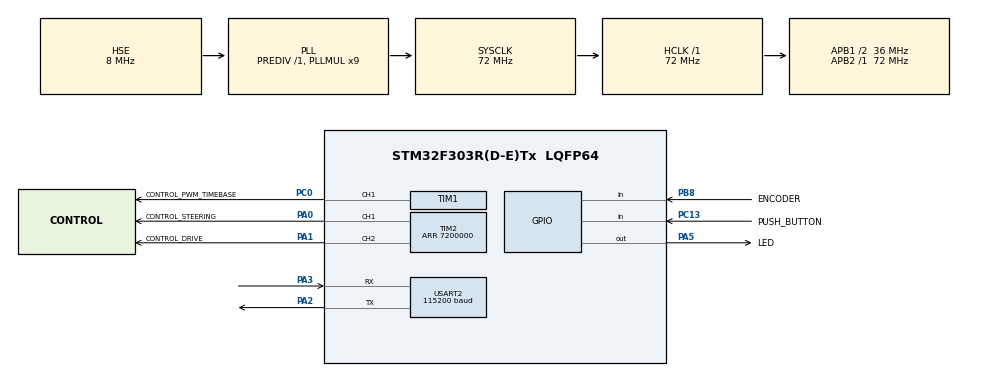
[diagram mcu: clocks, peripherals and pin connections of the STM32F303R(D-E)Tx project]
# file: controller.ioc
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FREERTOS.Tasks01=defaultTask,24,128,StartDefaultTask,Default,NULL,Dynamic,NULL,NULL
Mcu.Family=STM32F3
Mcu.Name=STM32F303R(D-E)Tx
Mcu.Package=LQFP64
NVIC.PriorityGroup=NVIC_PRIORITYGROUP_4
NVIC.USART2_IRQn=true\:5\:0\:false\:false\:true\:true\:true\:true
PA0.GPIO_Label=CONTROL_STEERING
PA0.Signal=S_TIM2_CH1_ETR
PA1.GPIO_Label=CONTROL_DRIVE
PA1.Signal=S_TIM2_CH2
PA2.Mode=Asynchronous
PA2.Signal=USART2_TX
PA3.Mode=Asynchronous
PA3.Signal=USART2_RX
PA5.GPIO_Label=LED
PA5.Signal=GPIO_Output
PB8.GPIO_Label=ENCODER
PB8.GPIO_PuPd=GPIO_PULLUP
PB8.Signal=GPIO_Input
PC0.GPIO_Label=CONTROL_PWM_TIMEBASE
PC0.Signal=S_TIM1_CH1
PC13.GPIO_Label=PUSH_BUTTON
PC13.Signal=GPIO_Input
PF0-OSC_IN.Mode=HSE-External-Oscillator
PF0-OSC_IN.Signal=RCC_OSC_IN
PF1-OSC_OUT.Mode=HSE-External-Oscillator
PF1-OSC_OUT.Signal=RCC_OSC_OUT
ProjectManager.HeapSize=0x200
ProjectManager.StackSize=0x400
ProjectManager.TargetToolchain=STM32CubeIDE
RCC.AHBFreq_Value=72000000
RCC.APB1CLKDivider=RCC_HCLK_DIV2
RCC.APB1Freq_Value=36000000
RCC.APB1TimFreq_Value=72000000
RCC.APB2Freq_Value=72000000
RCC.APB2TimFreq_Value=72000000
RCC.CortexFreq_Value=72000000
RCC.HCLKFreq_Value=72000000
RCC.HSE_VALUE=8000000
RCC.HSI_VALUE=8000000
RCC.LSE_VALUE=32768
RCC.PLLMUL=RCC_PLL_MUL9
RCC.PLLSourceVirtual=RCC_PLLSOURCE_HSE
RCC.RCC_MCODiv=RCC_MCODIV_128
RCC.SYSCLKFreq_VALUE=72000000
RCC.SYSCLKSourceVirtual=RCC_SYSCLKSOURCE_PLLCLK
RCC.USBFreq_Value=72000000
SH.S_TIM1_CH1.0=TIM1_CH1,PWM Generation1 CH1
SH.S_TIM2_CH1_ETR.0=TIM2_CH1,PWM Generation1 CH1
SH.S_TIM2_CH2.0=TIM2_CH2,PWM Generation2 CH2
TIM1.AutoReloadPreload=TIM_AUTORELOAD_PRELOAD_ENABLE
TIM1.Channel-PWM\ Generation1\ CH1=TIM_CHANNEL_1
TIM1.Period=9999
TIM1.Prescaler=71
TIM1.Pulse-PWM\ Generation1\ CH1=5000
TIM1.TIM_MasterOutputTrigger=TIM_TRGO_UPDATE
TIM2.Channel-PWM\ Generation1\ CH1=TIM_CHANNEL_1
TIM2.Channel-PWM\ Generation2\ CH2=TIM_CHANNEL_2
TIM2.Period=7200000
TIM2.Pulse-PWM\ Generation1\ CH1=108000
TIM2.Pulse-PWM\ Generation2\ CH2=108000
USART2.BaudRate=115200
USART2.VirtualMode-Asynchronous=VM_ASYNC
VP_FREERTOS_VS_CMSIS_V2.Mode=CMSIS_V2
VP_TIM1_VS_ClockSourceINT.Mode=Internal
VP_TIM2_VS_ClockSourceINT.Mode=Internal
VP_TIM2_VS_ClockSourceITR.Mode=TriggerSource_ITR0
VP_TIM2_VS_ControllerModeCombinedResetTrigger.Mode=Combined_Reset_Trigger_Mode
board=custom

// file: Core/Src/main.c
/* USER CODE BEGIN Header */
/**
  ******************************************************************************
  * @file           : main.c
  * @brief          : Main program body
  ******************************************************************************
  * @attention
  *
  * <h2><center>&copy; Copyright (c) 2020 STMicroelectronics.
  * All rights reserved.</center></h2>
  *
  * This software component is licensed by ST under BSD 3-Clause license,
  * the "License"; You may not use this file except in compliance with the
  * License. You may obtain a copy of the License at:
  *                        opensource.org/licenses/BSD-3-Clause
  *
  ******************************************************************************
  */
/* USER CODE END Header */

#include "main.h"
#include "cmsis_os.h"

TIM_HandleTypeDef htim1;
TIM_HandleTypeDef htim2;

UART_HandleTypeDef huart2;

/* Definitions for defaultTask */
osThreadId_t defaultTaskHandle;
const osThreadAttr_t defaultTask_attributes = {
  .name = "defaultTask",
  .priority = (osPriority_t) osPriorityNormal,
  .stack_size = 128 * 4
};

void SystemClock_Config(void);
static void MX_GPIO_Init(void);
static void MX_TIM1_Init(void);
static void MX_TIM2_Init(void);
static void MX_USART2_UART_Init(void);
void StartDefaultTask(void *argument);

int main(void)
{

  /* MCU Configuration--------------------------------------------------------*/

  /* Reset of all peripherals, Initializes the Flash interface and the Systick. */
  HAL_Init();

  /* Configure the system clock */
  SystemClock_Config();

  /* Initialize all configured peripherals */
  MX_GPIO_Init();
  MX_TIM1_Init();
  MX_TIM2_Init();
  MX_USART2_UART_Init();

  /* Init scheduler */
  osKernelInitialize();

  /* Create the thread(s) */
  /* creation of defaultTask */
  defaultTaskHandle = osThreadNew(StartDefaultTask, NULL, &defaultTask_attributes);

  /* Start scheduler */
  osKernelStart();

  /* We should never get here as control is now taken by the scheduler */
  /* Infinite loop */
  while (1)
  {

  }
}

void SystemClock_Config(void)
{
  RCC_OscInitTypeDef RCC_OscInitStruct = {0};
  RCC_ClkInitTypeDef RCC_ClkInitStruct = {0};
  RCC_PeriphCLKInitTypeDef PeriphClkInit = {0};

  /** Initializes the CPU, AHB and APB busses clocks
  */
  RCC_OscInitStruct.OscillatorType = RCC_OSCILLATORTYPE_HSE;
  RCC_OscInitStruct.HSEState = RCC_HSE_ON;
  RCC_OscInitStruct.HSIState = RCC_HSI_ON;
  RCC_OscInitStruct.PLL.PLLState = RCC_PLL_ON;
  RCC_OscInitStruct.PLL.PLLSource = RCC_PLLSOURCE_HSE;
  RCC_OscInitStruct.PLL.PLLMUL = RCC_PLL_MUL9;
  RCC_OscInitStruct.PLL.PREDIV = RCC_PREDIV_DIV1;
  if (HAL_RCC_OscConfig(&RCC_OscInitStruct) != HAL_OK)
  {
    Error_Handler();
  }
  /** Initializes the CPU, AHB and APB busses clocks
  */
  RCC_ClkInitStruct.ClockType = RCC_CLOCKTYPE_HCLK|RCC_CLOCKTYPE_SYSCLK
                              |RCC_CLOCKTYPE_PCLK1|RCC_CLOCKTYPE_PCLK2;
  RCC_ClkInitStruct.SYSCLKSource = RCC_SYSCLKSOURCE_PLLCLK;
  RCC_ClkInitStruct.AHBCLKDivider = RCC_SYSCLK_DIV1;
  RCC_ClkInitStruct.APB1CLKDivider = RCC_HCLK_DIV2;
  RCC_ClkInitStruct.APB2CLKDivider = RCC_HCLK_DIV1;

  if (HAL_RCC_ClockConfig(&RCC_ClkInitStruct, FLASH_LATENCY_2) != HAL_OK)
  {
    Error_Handler();
  }
  PeriphClkInit.PeriphClockSelection = RCC_PERIPHCLK_USART2|RCC_PERIPHCLK_TIM1
                              |RCC_PERIPHCLK_TIM2;
  PeriphClkInit.Usart2ClockSelection = RCC_USART2CLKSOURCE_PCLK1;
  PeriphClkInit.Tim1ClockSelection = RCC_TIM1CLK_HCLK;
  PeriphClkInit.Tim2ClockSelection = RCC_TIM2CLK_HCLK;
  if (HAL_RCCEx_PeriphCLKConfig(&PeriphClkInit) != HAL_OK)
  {
    Error_Handler();
  }
}

static void MX_TIM1_Init(void)
{

  TIM_ClockConfigTypeDef sClockSourceConfig = {0};
  TIM_MasterConfigTypeDef sMasterConfig = {0};
  TIM_OC_InitTypeDef sConfigOC = {0};
  TIM_BreakDeadTimeConfigTypeDef sBreakDeadTimeConfig = {0};

  htim1.Instance = TIM1;
  htim1.Init.Prescaler = 71;
  htim1.Init.CounterMode = TIM_COUNTERMODE_UP;
  htim1.Init.Period = 9999;
  htim1.Init.ClockDivision = TIM_CLOCKDIVISION_DIV1;
  htim1.Init.RepetitionCounter = 0;
  htim1.Init.AutoReloadPreload = TIM_AUTORELOAD_PRELOAD_ENABLE;
  if (HAL_TIM_Base_Init(&htim1) != HAL_OK)
  {
    Error_Handler();
  }
  sClockSourceConfig.ClockSource = TIM_CLOCKSOURCE_INTERNAL;
  if (HAL_TIM_ConfigClockSource(&htim1, &sClockSourceConfig) != HAL_OK)
  {
    Error_Handler();
  }
  if (HAL_TIM_PWM_Init(&htim1) != HAL_OK)
  {
    Error_Handler();
  }
  sMasterConfig.MasterOutputTrigger = TIM_TRGO_UPDATE;
  sMasterConfig.MasterOutputTrigger2 = TIM_TRGO2_RESET;
  sMasterConfig.MasterSlaveMode = TIM_MASTERSLAVEMODE_DISABLE;
  if (HAL_TIMEx_MasterConfigSynchronization(&htim1, &sMasterConfig) != HAL_OK)
  {
    Error_Handler();
  }
  sConfigOC.OCMode = TIM_OCMODE_PWM1;
  sConfigOC.Pulse = 5000;
  sConfigOC.OCPolarity = TIM_OCPOLARITY_HIGH;
  sConfigOC.OCNPolarity = TIM_OCNPOLARITY_HIGH;
  sConfigOC.OCFastMode = TIM_OCFAST_DISABLE;
  sConfigOC.OCIdleState = TIM_OCIDLESTATE_RESET;
  sConfigOC.OCNIdleState = TIM_OCNIDLESTATE_RESET;
  if (HAL_TIM_PWM_ConfigChannel(&htim1, &sConfigOC, TIM_CHANNEL_1) != HAL_OK)
  {
    Error_Handler();
  }
  sBreakDeadTimeConfig.OffStateRunMode = TIM_OSSR_DISABLE;
  sBreakDeadTimeConfig.OffStateIDLEMode = TIM_OSSI_DISABLE;
  sBreakDeadTimeConfig.LockLevel = TIM_LOCKLEVEL_OFF;
  sBreakDeadTimeConfig.DeadTime = 0;
  sBreakDeadTimeConfig.BreakState = TIM_BREAK_DISABLE;
  sBreakDeadTimeConfig.BreakPolarity = TIM_BREAKPOLARITY_HIGH;
  sBreakDeadTimeConfig.BreakFilter = 0;
  sBreakDeadTimeConfig.Break2State = TIM_BREAK2_DISABLE;
  sBreakDeadTimeConfig.Break2Polarity = TIM_BREAK2POLARITY_HIGH;
  sBreakDeadTimeConfig.Break2Filter = 0;
  sBreakDeadTimeConfig.AutomaticOutput = TIM_AUTOMATICOUTPUT_DISABLE;
  if (HAL_TIMEx_ConfigBreakDeadTime(&htim1, &sBreakDeadTimeConfig) != HAL_OK)
  {
    Error_Handler();
  }
  HAL_TIM_MspPostInit(&htim1);

}

static void MX_TIM2_Init(void)
{

  TIM_ClockConfigTypeDef sClockSourceConfig = {0};
  TIM_SlaveConfigTypeDef sSlaveConfig = {0};
  TIM_MasterConfigTypeDef sMasterConfig = {0};
  TIM_OC_InitTypeDef sConfigOC = {0};

  htim2.Instance = TIM2;
  htim2.Init.Prescaler = 0;
  htim2.Init.CounterMode = TIM_COUNTERMODE_UP;
  htim2.Init.Period = 7200000;
  htim2.Init.ClockDivision = TIM_CLOCKDIVISION_DIV1;
  htim2.Init.AutoReloadPreload = TIM_AUTORELOAD_PRELOAD_DISABLE;
  if (HAL_TIM_Base_Init(&htim2) != HAL_OK)
  {
    Error_Handler();
  }
  sClockSourceConfig.ClockSource = TIM_CLOCKSOURCE_INTERNAL;
  if (HAL_TIM_ConfigClockSource(&htim2, &sClockSourceConfig) != HAL_OK)
  {
    Error_Handler();
  }
  if (HAL_TIM_PWM_Init(&htim2) != HAL_OK)
  {
    Error_Handler();
  }
  sSlaveConfig.SlaveMode = TIM_SLAVEMODE_COMBINED_RESETTRIGGER;
  sSlaveConfig.InputTrigger = TIM_TS_ITR0;
  if (HAL_TIM_SlaveConfigSynchro(&htim2, &sSlaveConfig) != HAL_OK)
  {
    Error_Handler();
  }
  sMasterConfig.MasterOutputTrigger = TIM_TRGO_RESET;
  sMasterConfig.MasterSlaveMode = TIM_MASTERSLAVEMODE_DISABLE;
  if (HAL_TIMEx_MasterConfigSynchronization(&htim2, &sMasterConfig) != HAL_OK)
  {
    Error_Handler();
  }
  sConfigOC.OCMode = TIM_OCMODE_PWM1;
  sConfigOC.Pulse = 108000;
  sConfigOC.OCPolarity = TIM_OCPOLARITY_HIGH;
  sConfigOC.OCFastMode = TIM_OCFAST_DISABLE;
  if (HAL_TIM_PWM_ConfigChannel(&htim2, &sConfigOC, TIM_CHANNEL_1) != HAL_OK)
  {
    Error_Handler();
  }
  if (HAL_TIM_PWM_ConfigChannel(&htim2, &sConfigOC, TIM_CHANNEL_2) != HAL_OK)
  {
    Error_Handler();
  }
  HAL_TIM_MspPostInit(&htim2);

}

static void MX_USART2_UART_Init(void)
{

  huart2.Instance = USART2;
  huart2.Init.BaudRate = 115200;
  huart2.Init.WordLength = UART_WORDLENGTH_8B;
  huart2.Init.StopBits = UART_STOPBITS_1;
  huart2.Init.Parity = UART_PARITY_NONE;
  huart2.Init.Mode = UART_MODE_TX_RX;
  huart2.Init.HwFlowCtl = UART_HWCONTROL_NONE;
  huart2.Init.OverSampling = UART_OVERSAMPLING_16;
  huart2.Init.OneBitSampling = UART_ONE_BIT_SAMPLE_DISABLE;
  huart2.AdvancedInit.AdvFeatureInit = UART_ADVFEATURE_NO_INIT;
  if (HAL_UART_Init(&huart2) != HAL_OK)
  {
    Error_Handler();
  }

}

static void MX_GPIO_Init(void)
{
  GPIO_InitTypeDef GPIO_InitStruct = {0};

  /* GPIO Ports Clock Enable */
  __HAL_RCC_GPIOC_CLK_ENABLE();
  __HAL_RCC_GPIOF_CLK_ENABLE();
  __HAL_RCC_GPIOA_CLK_ENABLE();
  __HAL_RCC_GPIOB_CLK_ENABLE();

  /*Configure GPIO pin Output Level */
  HAL_GPIO_WritePin(LED_GPIO_Port, LED_Pin, GPIO_PIN_RESET);

  /*Configure GPIO pin : PUSH_BUTTON_Pin */
  GPIO_InitStruct.Pin = PUSH_BUTTON_Pin;
  GPIO_InitStruct.Mode = GPIO_MODE_INPUT;
  GPIO_InitStruct.Pull = GPIO_NOPULL;
  HAL_GPIO_Init(PUSH_BUTTON_GPIO_Port, &GPIO_InitStruct);

  /*Configure GPIO pin : LED_Pin */
  GPIO_InitStruct.Pin = LED_Pin;
  GPIO_InitStruct.Mode = GPIO_MODE_OUTPUT_PP;
  GPIO_InitStruct.Pull = GPIO_NOPULL;
  GPIO_InitStruct.Speed = GPIO_SPEED_FREQ_LOW;
  HAL_GPIO_Init(LED_GPIO_Port, &GPIO_InitStruct);

  /*Configure GPIO pin : ENCODER_Pin */
  GPIO_InitStruct.Pin = ENCODER_Pin;
  GPIO_InitStruct.Mode = GPIO_MODE_INPUT;
  GPIO_InitStruct.Pull = GPIO_PULLUP;
  HAL_GPIO_Init(ENCODER_GPIO_Port, &GPIO_InitStruct);

}

void StartDefaultTask(void *argument)
{
  /* USER CODE BEGIN 5 */
  HAL_StatusTypeDef status;
  uint8_t data = '.';
  /* Infinite loop */
  for(;;)
  {
	if (PUSH_BUTTON_STATE == GPIO_PIN_SET)
		LED_SET;
	else
		LED_RESET;

	status = HAL_UART_Receive(&CONSOLE, &data, 1, 1000);
	if (status == HAL_TIMEOUT)
	{
		data = '.';
		HAL_UART_AbortReceive(&CONSOLE);
	}
	status = HAL_UART_Transmit(&CONSOLE, &data, 1, 100);
    osDelay(250);

  }
  /* USER CODE END 5 */
}

void Error_Handler(void)
{
}

/************************ (C) COPYRIGHT STMicroelectronics *****END OF FILE****/
